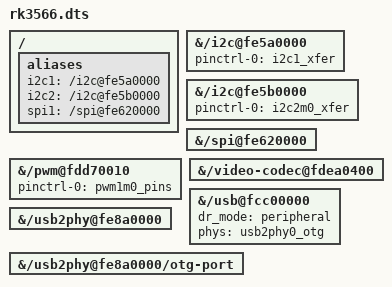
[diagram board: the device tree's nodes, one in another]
// Generated by `lemnos-ctl tree` from board "rk3566". Do not edit: change the
// board file or the SoC map, and generate again.
// Every fragment says why it is here. Node paths are the base tree's.
/dts-v1/;
/plugin/;
/ {
	// i2c: an I2C bus on the RK3566 (alias i2c1, the name "i2c-1") on GPIO11, GPIO12
	fragment@0 {
		target-path = "/i2c@fe5a0000";
		__overlay__ {
			status = "okay";
			pinctrl-names = "default";
			pinctrl-0 = <&i2c1_xfer>;
		};
	};
	// the runtime name comes out of alias i2c1
	fragment@1 {
		target-path = "/";
		__overlay__ {
			aliases { i2c1 = "/i2c@fe5a0000"; };
		};
	};
	// i2c: an I2C bus on the RK3566 (alias i2c2, the name "i2c-2") on GPIO13, GPIO14
	fragment@2 {
		target-path = "/i2c@fe5b0000";
		__overlay__ {
			status = "okay";
			pinctrl-names = "default";
			pinctrl-0 = <&i2c2m0_xfer>;
		};
	};
	// the runtime name comes out of alias i2c2
	fragment@3 {
		target-path = "/";
		__overlay__ {
			aliases { i2c2 = "/i2c@fe5b0000"; };
		};
	};
	// spi: an SPI controller on the RK3566 (alias spi1, the name "spidev1.0")
	fragment@4 {
		target-path = "/spi@fe620000";
		__overlay__ {
			status = "okay";
		};
	};
	// the runtime name comes out of alias spi1
	fragment@5 {
		target-path = "/";
		__overlay__ {
			aliases { spi1 = "/spi@fe620000"; };
		};
	};
	// pwm: a PWM block on the RK3566 (the PMU-side PWM 1) on GPIO16
	fragment@6 {
		target-path = "/pwm@fdd70010";
		__overlay__ {
			status = "okay";
			pinctrl-names = "default";
			pinctrl-0 = <&pwm1m0_pins>;
		};
	};
	// block: the VPU video decoder on the RK3566 (rockchip,rk3568-vpu)
	fragment@7 {
		target-path = "/video-codec@fdea0400";
		__overlay__ {
			status = "okay";
		};
	};
	// usb-peripheral: the USB 2 DRD (OTG) controller on the RK3566, port 0 (rockchip,rk3568-dwc3); device mode
	fragment@8 {
		target-path = "/usb@fcc00000";
		__overlay__ {
			status = "okay";
			dr_mode = "peripheral";
			phys = <&usb2phy0_otg>;
			phy-names = "usb2-phy";
		};
	};
	// needed by usb-otg0 (usb-peripheral): the USB 2 PHY that port 0 uses (rockchip,rk3568-usb2phy); disabled in the base tree
	fragment@9 {
		target-path = "/usb2phy@fe8a0000";
		__overlay__ {
			status = "okay";
		};
	};
	// needed by usb-otg0 (usb-peripheral): the OTG port of that USB 2 PHY, the one the controller is wired to (its phys)
	fragment@10 {
		target-path = "/usb2phy@fe8a0000/otg-port";
		__overlay__ {
			status = "okay";
		};
	};
	// No base named: lines the board gives to Lemnos are not checked against the base tree.
};
